# R7FA8M1AH register map
Vendor: Renesas; Series: RA8; File version: 1.2
CPU: CM85 r0p0, little endian, MPU, FPU, VTOR, 4 interrupt priority bits
Registers are 32-bit, read-write, reset 0x0 unless marked. A register's access mark holds for its fields unless they carry their own. Offsets are from the block's base; [hi:lo] are bit positions; {n}, {i} and the like mark numbered series; 'fields as' and 'values as' point back to an identical list.

## CEU — Capture Engine Unit
Base 0x40348000
Same registers: CEU_NS 0x50348000
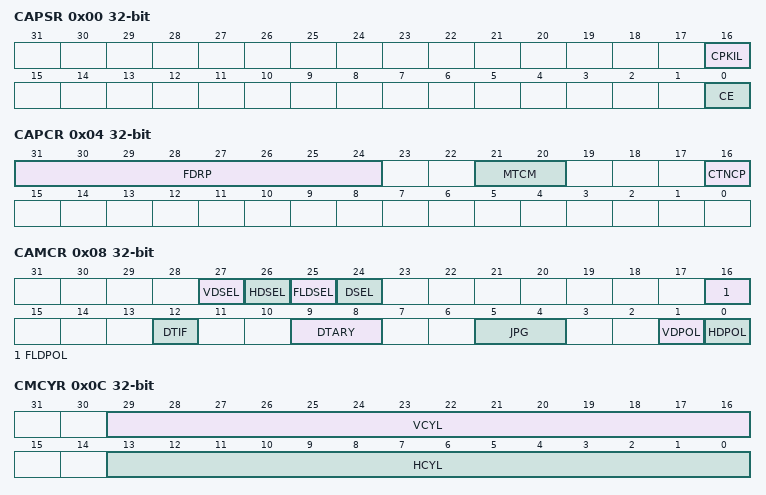
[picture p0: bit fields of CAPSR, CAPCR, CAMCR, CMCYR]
0x00 CAPSR — Capture Start Register
  [16] CPKIL — Write 1 to this bit to perform a software reset of capturing.
    0=Normal state; 1=Software reset of capturing
  [0] CE — Capture enable
    0=Stops capturing; 1=Starts capturing
0x04 CAPCR — Capture Control Register
  [31:24] FDRP — Set the frame drop interval in continuous-frame capture.
  [21:20] MTCM — Specify the unit for transferring data to a bus bridge module.
    0=Image capture: Y data and C data are transferred in 32-byte units Data fetch : Data is transferred in 32-byte units; 1=Image capture: Y data and C data are transferred in 64-byte units Data fetch : Data is transferred in 64-byte; 2=Image capture: Y data and C data are transferred in 128-byte units Data fetch : Data is transferred in 128-byte; 3=Image capture: Y data and C data are transferred in 256-byte units Data fetch : Data is transferred in 256-byte
  [16] CTNCP — When capturing is started with this bit set to 1, capturing continues until the CE bit in CAPSR is cleared to 0 or a software reset is initiated by the CPKIL bit in CAPSR (see ). Continuous capture must be set before capturing is started.
    0=One-frame capture when the CE bit is 1; 1=Continuous capture until the CE bit is cleared to 0
0x08 CAMCR — Capture interface control register
  [27] VDSEL — Sets the edge for capturing the vertical sync signal (VD) from an external module.
    0=VD is captured at the rising edge of the camera clock; 1=VD is captured at the falling edge of the camera clock
  [26] HDSEL — Sets the edge for capturing the horizontal sync signal (HD) from an external module.
    0=HD is captured at the rising edge of the camera clock; 1=HD is captured at the falling edge of the camera clock
  [25] FLDSEL — Sets the edge for capturing the field identification signal (FLD) from an external module.
    0=FLD is captured at the rising edge of the camera clock; 1=FLD is captured at the falling edge of the camera clock
  [24] DSEL — Sets the edge for fetching the image data (D7 to D0) from an external module.
    0=D7 to D0 are fetched at the rising edge of the camera clock; 1=D7 to D0 are fetched at the falling edge of the camera clock
  [16] FLDPOL — Sets the polarity of the field identification signal (FLD) from an external module.
    0=When the FLD signal is high-active, the field is detected as the top field and when low-active, the field is detected as the bottom field; 1=When the FLD signal is low-active, the field is detected as the top field and when high-active, the field is detected as the bottom field
  [12] DTIF — Sets the digital image input pins from which data is to be captured.
    0=Data input to 8-bit digital image input pins is captured; 1=Data input to 16-bit digital image input pins is captured
  [9:8] DTARY — Set the input order of the luminance component and chrominance component.
    0=8-bit interface: Image input data is fetched in the order of Cb0, Y0, Cr0, and Y1 16-bit interface: Image input data is fetched in the order of {Cb0, Y0} and {Cr0, Y1}; 1=8-bit interface: Image input data is fetched in the order of Cr0, Y0, Cb0, and Y1 16-bit interface: Image input data is fetched in the order of {Cr0, Y0} and {Cb0, Y1}; 2=8-bit interface: Image input data is fetched in the order of Y0, Cb0, Y1, and Cr0 16-bit interface: Image input data is fetched in the order of {Y0, Cb0} and {Y1, Cr0}; 3=8-bit interface: Image input data is fetched in the order of Y0, Cr0, Y1, and Cb0 16-bit interface: Image input data is fetched in the order of {Y0, Cr0} and {Y1, Cb0}
  [5:4] JPG — These bits select the fetched data type.
    0=Image capture mode (input data are separated into Y data and CbCr data for output to the memory); 1=Data synchronous fetch mode (specified size of input data are output to the specified memory addresses in order of input and in synchronization with the sync signal); 2=Data enable fetch mode (input data are fetched with HD as an enable signal and output to the specified addresses in memory in order of input); 3=Setting prohibited
  [1] VDPOL — Sets the polarity for detection of the vertical sync signal input from an external module.
    0=Vertical sync signal (VD) from an external module is detected as highactive; 1=Vertical sync signal (VD) from an external module is detected as low-active
  [0] HDPOL — Sets the polarity for detection of the horizontal sync signal input from an external module.
    0=Horizontal sync signal (HD) from an external module is detected as highactive; 1=Horizontal sync signal (HD) from an external module is detected as lowactive
0x0C CMCYR — Capture Interface Cycle Register
  [29:16] VCYL — Vertical HD Count of External Module
  [13:0] HCYL — Horizontal Cycle Count of External Module
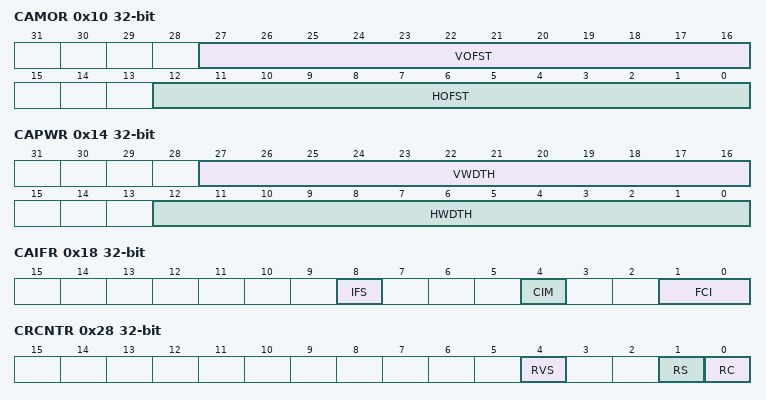
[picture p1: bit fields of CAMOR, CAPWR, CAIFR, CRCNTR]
0x10 CAMOR — Capture Interface Offset Register
  [27:16] VOFST — Specify the capture start location in terms of the HD count from a vertical sync signal (1-HD units).
  [12:0] HOFST — Specify the capture start location in terms of the number of clock cycles from a horizontal sync signal (1-cycle units).
0x14 CAPWR — Capture Interface Width Register
  [27:16] VWDTH — Specify the vertical capture period (4-HD units).
  [12:0] HWDTH — Specify the horizontal capture period.
0x18 CAIFR — Capture Interface Input Format Register
  [8] IFS — Sets the input mode for capturing images.
    0=Progressive; 1=Interlace
  [4] CIM — Sets the images to be captured.
    0=Capture of frame image (1 VD) or both-field image (2 VD); 1=Capture of one-field image (1 VD)
  [1:0] FCI — Set the timing to start capturing.
    0=Capture starts from the VD input immediately after the CEU activation regardless of it being a top or bottom field; 1=After the CEU activation, input of a top-field image is waited, and then capture starts from the top field; 2=After the CEU activation, input of a bottom-field image is waited, and then capture starts from the bottom field; 3=Setting prohibited
0x28 CRCNTR — CEU Register Control Register
  [4] RVS — Sets the timing to switch the register plane in both-field capture.
    0=Switches the register plane every 2 VD; 1=Switches the register plane every 1 VD
  [1] RS — Specifies which register plane is used by the CEU in synchronization with VD.
    0=Uses plane A of the register; 1=Uses plane B of the register
  [0] RC — Specifies switching of the register plane used by the CEU in synchronization with VD.
    0=Uses the specified register plane in synchronization with VD; 1=Switches the register plane in synchronization with VD
0x2C CRCMPR — CEU Register Forcible Control Register
  [0] RA — Indicates the register plane currently specified.
    0=Specifies plane A of the register; 1=Specifies plane B of the register
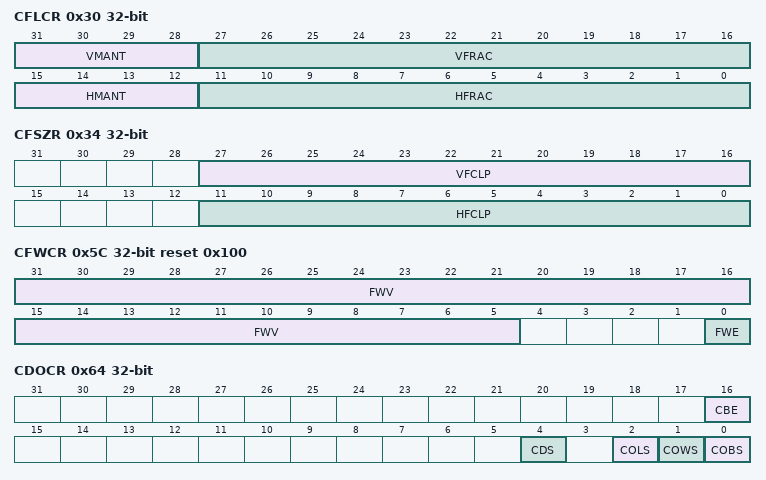
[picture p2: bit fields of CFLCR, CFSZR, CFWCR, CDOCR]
0x30 CFLCR — Capture Filter Control Register
  [31:28] VMANT — Mantissa Part of Vertical Scale-Down Factor
  [27:16] VFRAC — Fraction Part of Vertical Scale-Down Factor
  [15:12] HMANT — Mantissa Part of Horizontal Scale-Down Factor
  [11:0] HFRAC — Fraction Part of Horizontal Scale-Down Factor
0x34 CFSZR — Capture Filter Size Clip Register
  [27:16] VFCLP — Set the vertical clipping value of the filter output size (4-pixel units).
  [11:0] HFCLP — Specify the horizontal clipping value of the filter output size (4-pixel units).
0x38 CDWDR — Capture Destination Width Register
  [12:0] CHDW — Specify the horizontal image size in the memory area where the captured image is to be stored (4-byte units).
0x3C CDAYR — Capture Data Address Y Register
  [31:0] CAYR — Capture Data Address Y
0x40 CDACR — Capture Data Address C Register
  [31:0] CACR — Capture Data Address C
0x44 CDBYR — Capture Data Bottom-Field Address Y Register
  [31:0] CBYR — Set the address for storing the Y (luminance) component data of the captured bottom-field data (4-pixel units).
0x48 CDBCR — Capture Data Bottom-Field Address C Register
  [31:0] CBCR — Set the address for storing the C (chrominance) component data of the captured bottom-field data (4-pixel units).
0x4C CBDSR — Capture Bundle Destination Size Register
  [22:0] CBVS — Select the number of lines or number of bytes for output to the memory in a bundle write.
0x5C CFWCR reset 0x100 — Firewall Operation Control Register
  [31:5] FWV — Specify the upper limit of a write address.
  [0] FWE — With the setting of FWE = 1, when an address exceeds the value set with FWV, the address is retained and an interrupt source FWF is set. After this, the address is not incremented and data is overwritten on the upper limit address.
    0=Firewall is not activated; 1=Firewall is activated
0x60 CLFCR — Capture Low-Pass Filter Control Register
  [0] LPF — Enables or disables operation of the low-pass filter.
    0=Low-pass filter not used; 1=Low-pass filter used (only in the horizontal direction)
0x64 CDOCR — Capture Data Output Control Register
  [16] CBE — Controls the number of lines of captured data to be written to the memory.
    0=Normal write; 1=Bundle write
  [4] CDS — Sets the image format when outputting the image data captured in the YCbCr422 format to the memory.
    0=Converts the YCbCr422 format to the YCbCr420 format before outputting data to the memory; 1=Outputs data in the YCbCr422 format to the memory without conversion
  [2] COLS — Controls swapping in 32-bit units for data output from the CEU.
    0=Data is not swapped in 32-bit units; 1=Data is swapped in 32-bit units
  [1] COWS — Controls swapping in 16-bit units for data output from the CEU.
    0=Data is not swapped in 16-bit units; 1=Data is swapped in 16-bit units
  [0] COBS — Controls swapping in 8-bit units for data output from the CEU.
    0=Data is not swapped in 8-bit units; 1=Data is swapped in 8-bit units
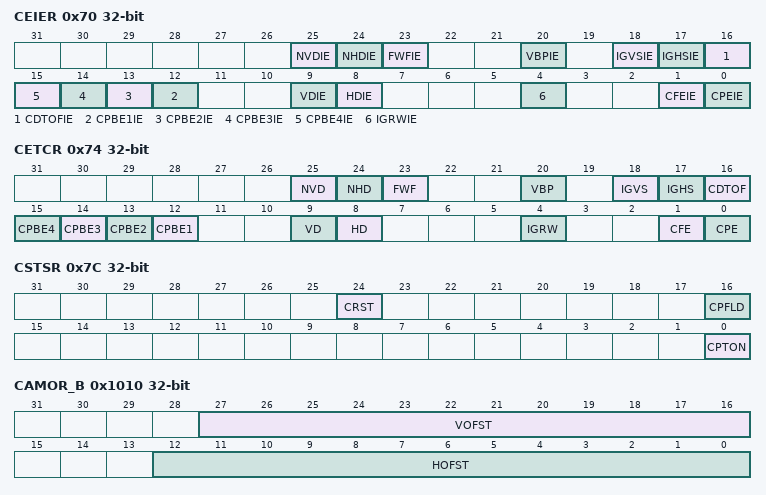
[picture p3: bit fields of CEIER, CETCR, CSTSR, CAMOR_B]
0x70 CEIER — Capture Event Interrupt Enable Register
  [25] NVDIE — Non-VD Interrupt Enable
    0=Disables a non-VD interrupt; 1=Enables a non-VD interrupt
  [24] NHDIE — Non-HD Interrupt Enable
    0=Disables a non-HD interrupt; 1=Enables a non-HD interrupt
  [23] FWFIE — FWF Interrupt Enable
    0=Disables a FWF interrupt; 1=Enables a FWF interrupt
  [20] VBPIE — VBP Interrupt Enable
    0=Disables a VBP interrupt; 1=Enables a VBP interrupt
  [18] IGVSIE — IGVS Interrupt Enable
    0=Disables an IGVS interrupt; 1=Enables an IGVS interrupt
  [17] IGHSIE — IGHS Interrupt Enable
    0=Disables an IGHS interrupt; 1=Enables an IGHS interrupt
  [16] CDTOFIE — CDTOF Interrupt Enable
    0=Disables a CDTOF interrupt; 1=Enables a CDTOF interrupt
  [n+11] CPBE{n}IE (n=1..4) — CPBE{n} Interrupt Enable
    0=Disables a CPBE{n} interrupt; 1=Enables a CPBE{n} interrupt
  [9] VDIE — VD Interrupt Enable
    0=Disables a VD interrupt; 1=Enables a VD interrupt
  [8] HDIE — HD Interrupt Enable
    0=Disables an HD interrupt; 1=Enables an HD interrupt
  [4] IGRWIE — Register-Access-During-Capture Interrupt Enable
    0=Disables a register-access-during-capture interrupt; 1=Enables a register-access-during-capture interrupt
  [1] CFEIE — CFE Interrupt Enable
    0=Disables a CFE interrupt; 1=Enables a CFE interrupt
  [0] CPEIE — One-Frame Capture End Interrupt Enable
    0=Disables a one-frame capture end interrupt; 1=Enables a one-frame capture end interrupt
0x74 CETCR (reset mask 0xFFFFFCFF) — Capture Event Flag Clear Register
  [25] NVD — An interrupt indicating that no VD was input.
  [24] NHD — An interrupt indicating that no HD was input.
  [23] FWF — The interrupt is generated when data is written to the address that exceeds the value specified with CFWCR.FMV.
  [20] VBP — An interrupt indicating that VD has been input while the CEU holds data (insufficient vertical-sync front porch).
  [18] IGVS — An interrupt generated when the number of VD cycles set in CMCYR differ from the number of VD cycles input from an external module.
  [17] IGHS — An interrupt generated when the number of HD cycles set in CMCYR differ from the number of HD cycles input from an external module.
  [16] CDTOF — An interrupt indicating that data overflowed in the CRAM of the write buffer
  [15] CPBE4 — An interrupt indicating that writing to CDBYR2 and CDBCR2 in a bundle write has finished.
  [14] CPBE3 — An interrupt indicating that writing to CDBYR and CDBCR in a bundle write has finished.
  [13] CPBE2 — An interrupt indicating that writing to CDAYR2 and CDACR2 in a bundle write has finished.
  [12] CPBE1 — An interrupt indicating that writing to CDAYR and CDACR in a bundle write has finished.
  [9] VD — An interrupt indicating that VD (vertical sync signal) was input from an external module.
  [8] HD — An interrupt indicating that HD (horizontal sync signal) was input from an external module.
  [4] IGRW — An interrupt indicating that during capturing, access was attempted to a register to which writing during operation is prohibited.
  [1] CFE — An interrupt indicating that capturing of one field from an external module has finished.
  [0] CPE — An interrupt indicating that capturing of one frame from an external module has finished.
0x7C CSTSR ro — Capture Status Register
  [24] CRST — Indicates which register plane is currently used.
    0=Plane A of the register is being used; 1=Plane B of the register is being used
  [16] CPFLD — Indicates which field is being captured.
    0=Bottom field is being captured; 1=Top field is being captured
  [0] CPTON — Indicates that the CEU is operating.
0x84 CDSSR ro — Capture Data Size Register
  [31:0] CDSS — Indicate the size of data written to the memory in data enable fetch.
0x90 CDAYR2 — Capture Data Address Y Register 2
  [31:0] CAYR2 — Capture Data Address Y
0x94 CDACR2 — Capture Data Address C Register 2
  [31:0] CACR2 — Capture Data Address C2
0x98 CDBYR2 — Capture Data Bottom-Field Address Y Register 2
  [31:0] CBYR2 — Set the address for storing the Y component data of the captured bottom-field data (4-pixel units).
0x9C CDBCR2 — Capture Data Bottom-Field Address C Register 2
  [31:0] CBCR2 — Set the address for storing the C component data of the captured bottom-field data (4-pixel units).
0xA0 AXIBUSCTL2 — AXI Bus Control Register 2
  [3:0] AWCACHE — AWCACHE[3:0] Signals for Capture Engine Unit
0x1010 CAMOR_B — Capture Interface Offset Register
  fields as CAMOR
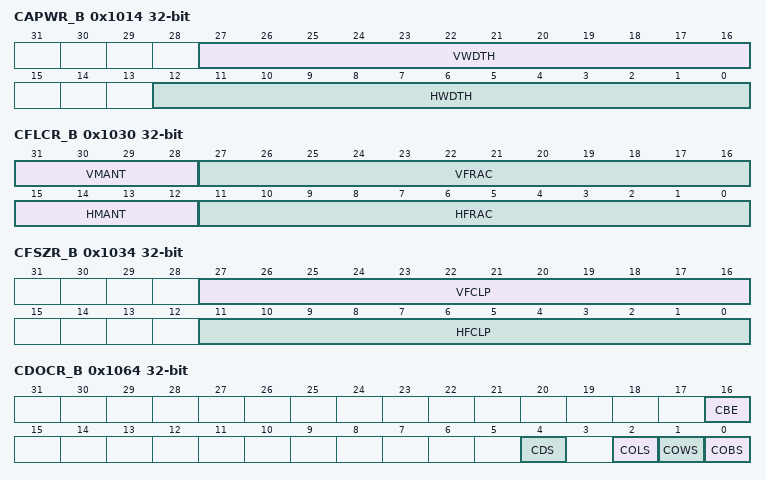
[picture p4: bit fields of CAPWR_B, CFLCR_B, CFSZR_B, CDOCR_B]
0x1014 CAPWR_B — Capture Interface Width Register
  fields as CAPWR
0x1030 CFLCR_B — Capture Filter Control Register
  fields as CFLCR
0x1034 CFSZR_B — Capture Filter Size Clip Register
  fields as CFSZR
0x1038 CDWDR_B — Capture Destination Width Register
  fields as CDWDR
0x103C CDAYR_B — Capture Data Address Y Register
  [31:0] CAYR — Capture Data Address Y
0x1040 CDACR_B — Capture Data Address C Register
  [31:0] CACR — Capture Data Address C
0x1044 CDBYR_B — Capture Data Bottom-Field Address Y Register
  fields as CDBYR
0x1048 CDBCR_B — Capture Data Bottom-Field Address C Register
  fields as CDBCR
0x104C CBDSR_B — Capture Bundle Destination Size Register
  fields as CBDSR
0x1060 CLFCR_B — Capture Low-Pass Filter Control Register
  fields as CLFCR
0x1064 CDOCR_B — Capture Data Output Control Register
  fields as CDOCR
0x1090 CDAYR2_B — Capture Data Address Y Register 2
  [31:0] CAYR2 — Capture Data Address Y
0x1094 CDACR2_B — Capture Data Address C Register 2
  [31:0] CACR2 — Capture Data Address C2
0x1098 CDBYR2_B — Capture Data Bottom-Field Address Y Register 2
  fields as CDBYR2
0x109C CDBCR2_B — Capture Data Bottom-Field Address C Register 2
  fields as CDBCR2
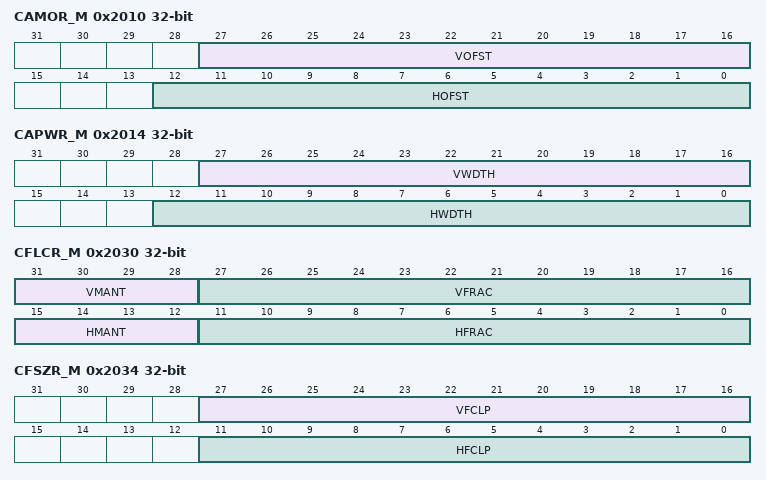
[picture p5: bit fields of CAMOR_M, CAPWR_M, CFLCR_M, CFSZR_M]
0x2010 CAMOR_M — Capture Interface Offset Register
  fields as CAMOR
0x2014 CAPWR_M — Capture Interface Width Register
  fields as CAPWR
0x2030 CFLCR_M — Capture Filter Control Register
  fields as CFLCR
0x2034 CFSZR_M — Capture Filter Size Clip Register
  fields as CFSZR
0x2038 CDWDR_M — Capture Destination Width Register
  fields as CDWDR
0x203C CDAYR_M — Capture Data Address Y Register
  [31:0] CAYR — Capture Data Address Y
0x2040 CDACR_M — Capture Data Address C Register
  [31:0] CACR — Capture Data Address C
0x2044 CDBYR_M — Capture Data Bottom-Field Address Y Register
  fields as CDBYR
0x2048 CDBCR_M — Capture Data Bottom-Field Address C Register
  fields as CDBCR
0x204C CBDSR_M — Capture Bundle Destination Size Register
  fields as CBDSR
0x2060 CLFCR_M — Capture Low-Pass Filter Control Register
  fields as CLFCR
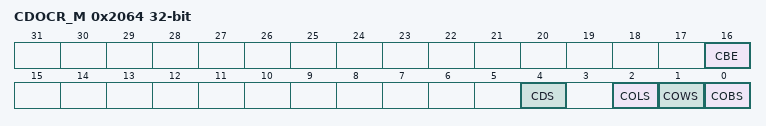
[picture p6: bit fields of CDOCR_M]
0x2064 CDOCR_M — Capture Data Output Control Register
  fields as CDOCR
0x2090 CDAYR2_M — Capture Data Address Y Register 2
  [31:0] CAYR2 — Capture Data Address Y
0x2094 CDACR2_M — Capture Data Address C Register 2
  [31:0] CACR2 — Capture Data Address C2
0x2098 CDBYR2_M — Capture Data Bottom-Field Address Y Register 2
  fields as CDBYR2
0x209C CDBCR2_M — Capture Data Bottom-Field Address C Register 2
  fields as CDBCR2
